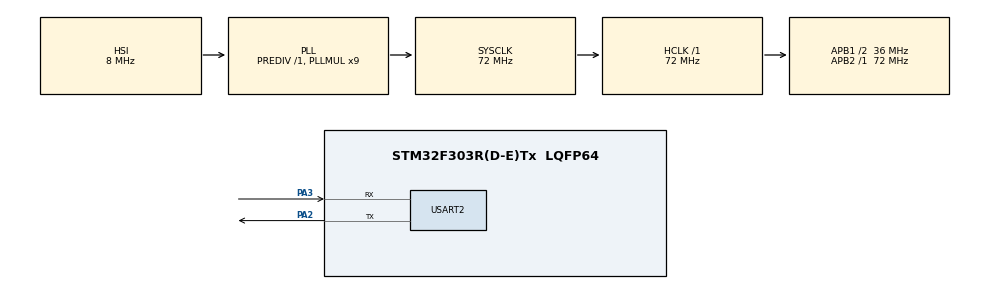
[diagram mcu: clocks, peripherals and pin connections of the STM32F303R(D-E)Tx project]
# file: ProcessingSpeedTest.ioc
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Mcu.Family=STM32F3
Mcu.Name=STM32F303R(D-E)Tx
Mcu.Package=LQFP64
NVIC.PriorityGroup=NVIC_PRIORITYGROUP_4
PA2.Mode=Asynchronous
PA2.Signal=USART2_TX
PA3.Mode=Asynchronous
PA3.Signal=USART2_RX
ProjectManager.HeapSize=0x200
ProjectManager.StackSize=0x400
ProjectManager.TargetToolchain=STM32CubeIDE
RCC.AHBFreq_Value=72000000
RCC.APB1CLKDivider=RCC_HCLK_DIV2
RCC.APB1Freq_Value=36000000
RCC.APB1TimFreq_Value=72000000
RCC.APB2Freq_Value=72000000
RCC.APB2TimFreq_Value=72000000
RCC.CortexFreq_Value=72000000
RCC.HCLKFreq_Value=72000000
RCC.HSE_VALUE=8000000
RCC.HSI_VALUE=8000000
RCC.LSE_VALUE=32768
RCC.PLLMUL=RCC_PLL_MUL9
RCC.SYSCLKFreq_VALUE=72000000
RCC.SYSCLKSourceVirtual=RCC_SYSCLKSOURCE_PLLCLK
RCC.USBFreq_Value=72000000
USART2.VirtualMode-Asynchronous=VM_ASYNC
board=custom

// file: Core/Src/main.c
/* USER CODE BEGIN Header */
/**
  ******************************************************************************
  * @file           : main.c
  * @brief          : Main program body
  ******************************************************************************
  * @attention
  *
  * Copyright (c) 2024 STMicroelectronics.
  * All rights reserved.
  *
  * This software is licensed under terms that can be found in the LICENSE file
  * in the root directory of this software component.
  * If no LICENSE file comes with this software, it is provided AS-IS.
  *
  ******************************************************************************
  */
/* USER CODE END Header */
#include "main.h"

/* USER CODE BEGIN Includes */
#include <stdio.h>
#include <math.h>
/* USER CODE END Includes */

/* USER CODE BEGIN PTD */
UART_HandleTypeDef huart2;
/* USER CODE END PTD */

/* USER CODE BEGIN PD */
#define PUTCHAR_PROTOTYPE int __io_putchar(int ch)
/* USER CODE END PD */

UART_HandleTypeDef huart2;

void SystemClock_Config(void);
static void MX_GPIO_Init(void);
static void MX_USART2_UART_Init(void);

/* USER CODE BEGIN 0 */
void func1(){
	int a = 0;
	for (int i=0; i<pow(10,5); i++){
		a++;
	}
}
/* USER CODE END 0 */

int main(void)
{

  /* MCU Configuration--------------------------------------------------------*/

  /* Reset of all peripherals, Initializes the Flash interface and the Systick. */
  HAL_Init();

  /* Configure the system clock */
  SystemClock_Config();

  /* Initialize all configured peripherals */
  MX_GPIO_Init();
  MX_USART2_UART_Init();
  /* USER CODE BEGIN 2 */

  uint32_t start_tick = HAL_GetTick();
  int nr_iter = 100;
  for (int i=0; i<nr_iter; i++){
	  func1();
  }
  uint32_t end_tick = HAL_GetTick();
  double time = (end_tick - start_tick)/nr_iter;
  printf("\rProcessing speed = %.2f [MHz]\n\r", (double)HAL_RCC_GetSysClockFreq()/(uint32_t)pow(10,6));
  printf("Execution time = %.2f [ms]\n\r", time);
  /* USER CODE END 2 */

  /* Infinite loop */
  while (1)
  {

  }
}

void SystemClock_Config(void)
{
  RCC_OscInitTypeDef RCC_OscInitStruct = {0};
  RCC_ClkInitTypeDef RCC_ClkInitStruct = {0};
  RCC_PeriphCLKInitTypeDef PeriphClkInit = {0};

  /** Initializes the RCC Oscillators according to the specified parameters
  * in the RCC_OscInitTypeDef structure.
  */
  RCC_OscInitStruct.OscillatorType = RCC_OSCILLATORTYPE_HSI;
  RCC_OscInitStruct.HSIState = RCC_HSI_ON;
  RCC_OscInitStruct.HSICalibrationValue = RCC_HSICALIBRATION_DEFAULT;
  RCC_OscInitStruct.PLL.PLLState = RCC_PLL_ON;
  RCC_OscInitStruct.PLL.PLLSource = RCC_PLLSOURCE_HSI;
  RCC_OscInitStruct.PLL.PLLMUL = RCC_PLL_MUL9;
  RCC_OscInitStruct.PLL.PREDIV = RCC_PREDIV_DIV1;
  if (HAL_RCC_OscConfig(&RCC_OscInitStruct) != HAL_OK)
  {
    Error_Handler();
  }

  /** Initializes the CPU, AHB and APB buses clocks
  */
  RCC_ClkInitStruct.ClockType = RCC_CLOCKTYPE_HCLK|RCC_CLOCKTYPE_SYSCLK
                              |RCC_CLOCKTYPE_PCLK1|RCC_CLOCKTYPE_PCLK2;
  RCC_ClkInitStruct.SYSCLKSource = RCC_SYSCLKSOURCE_PLLCLK;
  RCC_ClkInitStruct.AHBCLKDivider = RCC_SYSCLK_DIV1;
  RCC_ClkInitStruct.APB1CLKDivider = RCC_HCLK_DIV2;
  RCC_ClkInitStruct.APB2CLKDivider = RCC_HCLK_DIV1;

  if (HAL_RCC_ClockConfig(&RCC_ClkInitStruct, FLASH_LATENCY_2) != HAL_OK)
  {
    Error_Handler();
  }
  PeriphClkInit.PeriphClockSelection = RCC_PERIPHCLK_USART2;
  PeriphClkInit.Usart2ClockSelection = RCC_USART2CLKSOURCE_PCLK1;
  if (HAL_RCCEx_PeriphCLKConfig(&PeriphClkInit) != HAL_OK)
  {
    Error_Handler();
  }
}

static void MX_USART2_UART_Init(void)
{

  huart2.Instance = USART2;
  huart2.Init.BaudRate = 38400;
  huart2.Init.WordLength = UART_WORDLENGTH_8B;
  huart2.Init.StopBits = UART_STOPBITS_1;
  huart2.Init.Parity = UART_PARITY_NONE;
  huart2.Init.Mode = UART_MODE_TX_RX;
  huart2.Init.HwFlowCtl = UART_HWCONTROL_NONE;
  huart2.Init.OverSampling = UART_OVERSAMPLING_16;
  huart2.Init.OneBitSampling = UART_ONE_BIT_SAMPLE_DISABLE;
  huart2.AdvancedInit.AdvFeatureInit = UART_ADVFEATURE_NO_INIT;
  if (HAL_UART_Init(&huart2) != HAL_OK)
  {
    Error_Handler();
  }

}

static void MX_GPIO_Init(void)
{

  /* GPIO Ports Clock Enable */
  __HAL_RCC_GPIOA_CLK_ENABLE();

}

/* USER CODE BEGIN 4 */
PUTCHAR_PROTOTYPE
{
  /* Place your implementation of fputc here */
  /* e.g. write a character to the USART1 and Loop until the end of transmission */
  HAL_UART_Transmit(&huart2, (uint8_t *)&ch, 1, 0xFFFF);

  return ch;
}
/* USER CODE END 4 */

void Error_Handler(void)
{
  __disable_irq();
  while (1)
  {
  }
}
